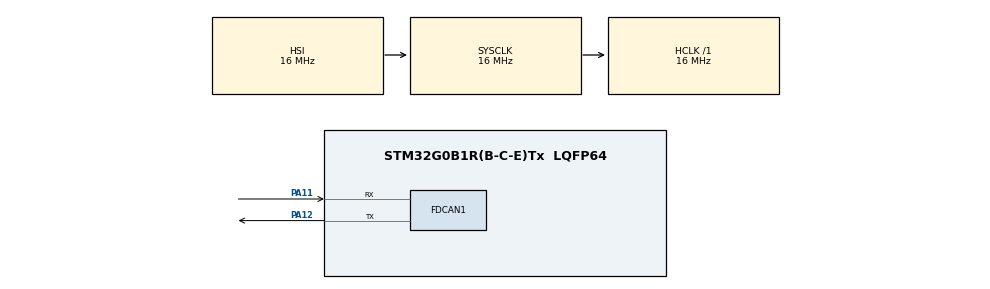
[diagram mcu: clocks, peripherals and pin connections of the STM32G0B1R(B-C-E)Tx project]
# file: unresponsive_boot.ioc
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FDCAN1.AutoRetransmission=ENABLE
FDCAN1.CalculateBaudRateNominal=1000000
FDCAN1.CalculateTimeBitNominal=1000
FDCAN1.CalculateTimeQuantumNominal=62.5
FDCAN1.DataSyncJumpWidth=4
FDCAN1.DataTimeSeg1=12
FDCAN1.DataTimeSeg2=3
FDCAN1.ExtFiltersNbr=2
FDCAN1.NominalPrescaler=1
FDCAN1.NominalSyncJumpWidth=4
FDCAN1.NominalTimeSeg1=12
FDCAN1.NominalTimeSeg2=3
FDCAN1.ProtocolException=ENABLE
FDCAN1.TransmitPause=ENABLE
Mcu.Family=STM32G0
Mcu.Name=STM32G0B1R(B-C-E)Tx
Mcu.Package=LQFP64
NVIC.TIM16_FDCAN_IT0_IRQn=true\:0\:0\:false\:false\:true\:true\:true\:true
NVIC.TIM17_FDCAN_IT1_IRQn=true\:0\:0\:false\:false\:true\:true\:true\:true
PA11\ [PA9].GPIO_Mode=GPIO_MODE_AF_PP
PA11\ [PA9].GPIO_PuPd=GPIO_NOPULL
PA11\ [PA9].GPIO_Speed=GPIO_SPEED_FREQ_LOW
PA11\ [PA9].Mode=FDCAN_Activate
PA11\ [PA9].PinState=GPIO_PIN_RESET
PA11\ [PA9].Signal=FDCAN1_RX
PA12\ [PA10].GPIO_Mode=GPIO_MODE_AF_PP
PA12\ [PA10].GPIO_PuPd=GPIO_NOPULL
PA12\ [PA10].GPIO_Speed=GPIO_SPEED_FREQ_LOW
PA12\ [PA10].Mode=FDCAN_Activate
PA12\ [PA10].PinState=GPIO_PIN_RESET
PA12\ [PA10].Signal=FDCAN1_TX
PA13.Mode=Serial_Wire
PA13.Signal=SYS_SWDIO
PA14-BOOT0.Mode=Serial_Wire
PA14-BOOT0.Signal=SYS_SWCLK
ProjectManager.HeapSize=0xF00
ProjectManager.StackSize=0x400
ProjectManager.TargetToolchain=MDK-ARM V5.32
RCC.ADCFreq_Value=16000000
RCC.AHBFreq_Value=16000000
RCC.CortexFreq_Value=16000000
RCC.EXTERNAL_CLOCK_VALUE=48000
RCC.HCLKFreq_Value=16000000
RCC.HSE_VALUE=8000000
RCC.HSI48_VALUE=48000000
RCC.HSI_VALUE=16000000
RCC.LSE_VALUE=32768
RCC.SYSCLKFreq_VALUE=16000000
RCC.USBFreq_Value=48000000
RCC.VCOOutputFreq_Value=128000000
TIM3.AutoReloadPreload=TIM_AUTORELOAD_PRELOAD_ENABLE
TIM3.Period=10000-1
TIM3.Prescaler=8-1
VP_SYS_VS_DBSignals.Mode=DisableDeadBatterySignals
VP_TIM3_VS_ClockSourceINT.Mode=Internal
board=custom

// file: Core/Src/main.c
/* USER CODE BEGIN Header */
/**
  ******************************************************************************
  * @file           : main.c
  * @brief          : Main program body
  ******************************************************************************
  * @attention
  *
  * Copyright (c) 2023 STMicroelectronics.
  * All rights reserved.
  *
  * This software is licensed under terms that can be found in the LICENSE file
  * in the root directory of this software component.
  * If no LICENSE file comes with this software, it is provided AS-IS.
  *
  ******************************************************************************
  */
/* USER CODE END Header */
#include "main.h"

/* USER CODE BEGIN Includes */
#include "sys.h"
#include "comm_update_handle.h"
#include "flash_update_handle.h"
#include "CAN_CircularBuf.h"
#include "SEGGER_RTT.h"
/* USER CODE END Includes */

FDCAN_HandleTypeDef hfdcan1;

TIM_HandleTypeDef htim3;

void SystemClock_Config(void);
static void MX_GPIO_Init(void);
static void MX_FDCAN1_Init(void);
static void MX_TIM3_Init(void);

int main(void)
{

  /* MCU Configuration--------------------------------------------------------*/

  /* Reset of all peripherals, Initializes the Flash interface and the Systick. */
  HAL_Init();
  /* USER CODE BEGIN Init */
  SEGGER_RTT_printf(0,"IN BOOT\r\n");
  /* USER CODE END Init */

  /* Configure the system clock */
  SystemClock_Config();

  /* Initialize all configured peripherals */
  MX_GPIO_Init();
  MX_FDCAN1_Init();
  MX_TIM3_Init();
  /* USER CODE BEGIN 2 */

  gt_comm_update_handle.tcomm_update_data.u8FWUpateStatus = FIRM_IN_BOOTLOADER;
  BootFlag_Diag();

  /* USER CODE END 2 */

  /* Infinite loop */
  /* USER CODE BEGIN WHILE */
  while (1)
  {
	CAN_DataDecode();
	ChipFlashDownload_Process();
	AppUpdate_Process();
    /* USER CODE END WHILE */

  }
}

void SystemClock_Config(void)
{
  RCC_OscInitTypeDef RCC_OscInitStruct = {0};
  RCC_ClkInitTypeDef RCC_ClkInitStruct = {0};

  /** Configure the main internal regulator output voltage
  */
  HAL_PWREx_ControlVoltageScaling(PWR_REGULATOR_VOLTAGE_SCALE1);

  /** Initializes the RCC Oscillators according to the specified parameters
  * in the RCC_OscInitTypeDef structure.
  */
  RCC_OscInitStruct.OscillatorType = RCC_OSCILLATORTYPE_HSI;
  RCC_OscInitStruct.HSIState = RCC_HSI_ON;
  RCC_OscInitStruct.HSIDiv = RCC_HSI_DIV1;
  RCC_OscInitStruct.HSICalibrationValue = RCC_HSICALIBRATION_DEFAULT;
  RCC_OscInitStruct.PLL.PLLState = RCC_PLL_NONE;
  if (HAL_RCC_OscConfig(&RCC_OscInitStruct) != HAL_OK)
  {
    Error_Handler();
  }

  /** Initializes the CPU, AHB and APB buses clocks
  */
  RCC_ClkInitStruct.ClockType = RCC_CLOCKTYPE_HCLK|RCC_CLOCKTYPE_SYSCLK
                              |RCC_CLOCKTYPE_PCLK1;
  RCC_ClkInitStruct.SYSCLKSource = RCC_SYSCLKSOURCE_HSI;
  RCC_ClkInitStruct.AHBCLKDivider = RCC_SYSCLK_DIV1;
  RCC_ClkInitStruct.APB1CLKDivider = RCC_HCLK_DIV1;

  if (HAL_RCC_ClockConfig(&RCC_ClkInitStruct, FLASH_LATENCY_0) != HAL_OK)
  {
    Error_Handler();
  }
}

static void MX_FDCAN1_Init(void)
{

  hfdcan1.Instance = FDCAN1;
  hfdcan1.Init.ClockDivider = FDCAN_CLOCK_DIV1;
  hfdcan1.Init.FrameFormat = FDCAN_FRAME_CLASSIC;
  hfdcan1.Init.Mode = FDCAN_MODE_NORMAL;
  hfdcan1.Init.AutoRetransmission = ENABLE;
  hfdcan1.Init.TransmitPause = ENABLE;
  hfdcan1.Init.ProtocolException = ENABLE;
  hfdcan1.Init.NominalPrescaler = 1;
  hfdcan1.Init.NominalSyncJumpWidth = 4;
  hfdcan1.Init.NominalTimeSeg1 = 12;
  hfdcan1.Init.NominalTimeSeg2 = 3;
  hfdcan1.Init.DataPrescaler = 1;
  hfdcan1.Init.DataSyncJumpWidth = 4;
  hfdcan1.Init.DataTimeSeg1 = 12;
  hfdcan1.Init.DataTimeSeg2 = 3;
  hfdcan1.Init.StdFiltersNbr = 0;
  hfdcan1.Init.ExtFiltersNbr = 2;
  hfdcan1.Init.TxFifoQueueMode = FDCAN_TX_FIFO_OPERATION;
  if (HAL_FDCAN_Init(&hfdcan1) != HAL_OK)
  {
    Error_Handler();
  }
  /* USER CODE BEGIN FDCAN1_Init 2 */
    if (HAL_FDCAN_ActivateNotification(&hfdcan1, FDCAN_IT_LIST_RX_FIFO0, 0) != HAL_OK) //FDCAN_IT_RX_FIFO0_NEW_MESSAGE
    {
        Error_Handler();
    }

    if (HAL_FDCAN_ActivateNotification(&hfdcan1, FDCAN_IT_BUS_OFF, 0) != HAL_OK)
    {
        Error_Handler();
    }

	if (HAL_FDCAN_Start(&hfdcan1) != HAL_OK)
	{
		Error_Handler();
	}

	can_circulbuf_init();
  /* USER CODE END FDCAN1_Init 2 */

}

static void MX_TIM3_Init(void)
{

  TIM_ClockConfigTypeDef sClockSourceConfig = {0};
  TIM_MasterConfigTypeDef sMasterConfig = {0};

  htim3.Instance = TIM3;
  htim3.Init.Prescaler = 8-1;
  htim3.Init.CounterMode = TIM_COUNTERMODE_UP;
  htim3.Init.Period = 10000-1;
  htim3.Init.ClockDivision = TIM_CLOCKDIVISION_DIV1;
  htim3.Init.AutoReloadPreload = TIM_AUTORELOAD_PRELOAD_ENABLE;
  if (HAL_TIM_Base_Init(&htim3) != HAL_OK)
  {
    Error_Handler();
  }
  sClockSourceConfig.ClockSource = TIM_CLOCKSOURCE_INTERNAL;
  if (HAL_TIM_ConfigClockSource(&htim3, &sClockSourceConfig) != HAL_OK)
  {
    Error_Handler();
  }
  sMasterConfig.MasterOutputTrigger = TIM_TRGO_RESET;
  sMasterConfig.MasterSlaveMode = TIM_MASTERSLAVEMODE_DISABLE;
  if (HAL_TIMEx_MasterConfigSynchronization(&htim3, &sMasterConfig) != HAL_OK)
  {
    Error_Handler();
  }
  /* USER CODE BEGIN TIM3_Init 2 */
	HAL_TIM_Base_Start_IT(&htim3);
  /* USER CODE END TIM3_Init 2 */

}

static void MX_GPIO_Init(void)
{

  /* GPIO Ports Clock Enable */
  __HAL_RCC_GPIOA_CLK_ENABLE();

}

void Error_Handler(void)
{
  __disable_irq();
  while (1)
  {
  }
}
